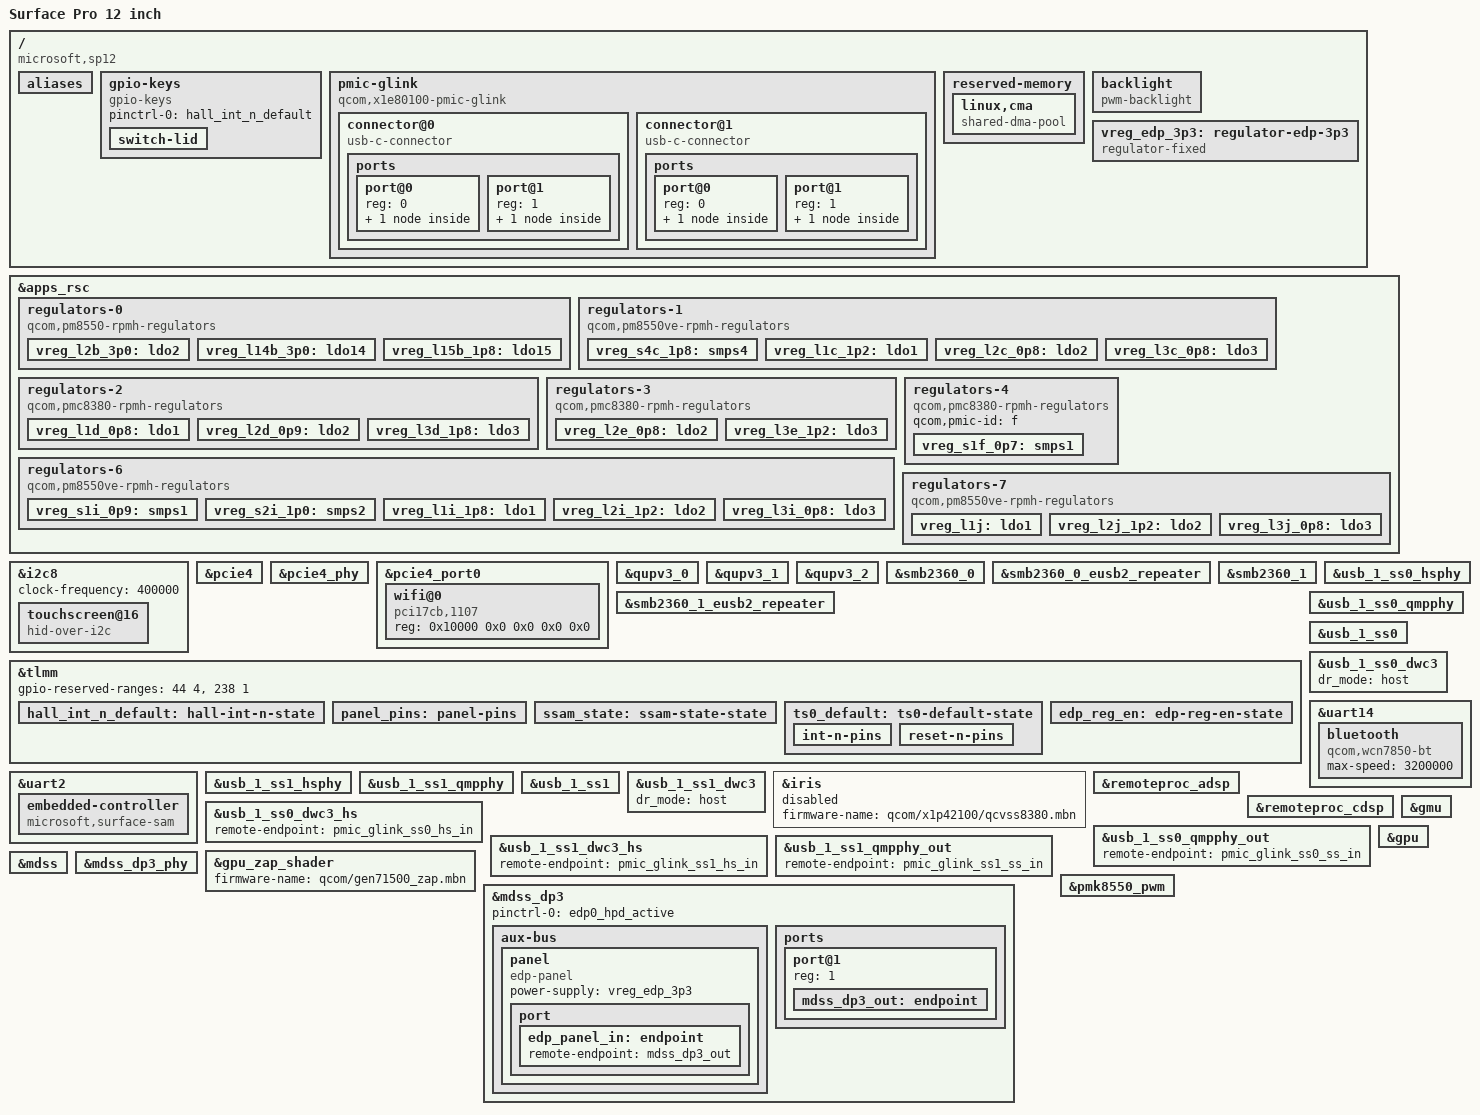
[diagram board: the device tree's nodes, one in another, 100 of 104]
// SPDX-License-Identifier: BSD-3-Clause
/*
 * Copyright (c) 2023 Qualcomm Innovation Center, Inc. All rights reserved.
 * Copyright (c) 2024, Linaro Limited
 * Copyright (c) 2025, Jens Glathe
 */

/dts-v1/;

#include <dt-bindings/gpio/gpio.h>
#include <dt-bindings/input/gpio-keys.h>
#include <dt-bindings/input/input.h>
#include <dt-bindings/pinctrl/qcom,pmic-gpio.h>
#include <dt-bindings/regulator/qcom,rpmh-regulator.h>
#include <dt-bindings/clock/qcom,x1e80100-tcsr.h>

#include "x1p42100.dtsi"
#include "x1e80100-pmics.dtsi"

/delete-node/ &pmc8380_6;
/delete-node/ &pmc8380_6_thermal;
/delete-node/ &pm8010;
/delete-node/ &pm8010_thermal;

/ {
	model = "Surface Pro 12 inch";
	compatible = "microsoft,sp12", "qcom,x1p42100";
	chassis-type = "tablet";

	aliases {
		serial0 = &uart2;
		serial1 = &uart14;
	};




	gpio-keys {
		compatible = "gpio-keys";

		pinctrl-0 = <&hall_int_n_default>;
		pinctrl-names = "default";

		switch-lid {
			gpios = <&tlmm 2 GPIO_ACTIVE_LOW>;
			linux,input-type = <EV_SW>;
			linux,code = <SW_LID>;
			wakeup-source;
			wakeup-event-action = <EV_ACT_DEASSERTED>;
		};
		
	};


	pmic-glink {
		compatible = "qcom,x1e80100-pmic-glink","qcom,sm8550-pmic-glink",
			     "qcom,pmic-glink";
		#address-cells = <1>;
		#size-cells = <0>;

		connector@0 {
			compatible = "usb-c-connector";
			reg = <0>;
			power-role = "dual";
			data-role = "host";
			
			ports {
				#address-cells = <1>;
				#size-cells = <0>;

				port@0 {
					reg = <0>;

					pmic_glink_ss0_hs_in: endpoint {
						remote-endpoint = <&usb_1_ss0_dwc3_hs>;
					};
				};

				port@1 {
					reg = <1>;

					pmic_glink_ss0_ss_in: endpoint {
						remote-endpoint = <&usb_1_ss0_qmpphy_out>;
					};
				};
			
			};
		};

		/* User-adjacent port */
		connector@1 {
			compatible = "usb-c-connector";
			reg = <1>;
			power-role = "dual";
			data-role = "host";
			
			ports {
				#address-cells = <1>;
				#size-cells = <0>;

				port@0 {
					reg = <0>;

					pmic_glink_ss1_hs_in: endpoint {
						remote-endpoint = <&usb_1_ss1_dwc3_hs>;
					};
				};

				port@1 {
					reg = <1>;

					pmic_glink_ss1_ss_in: endpoint {
						remote-endpoint = <&usb_1_ss1_qmpphy_out>;
					};
				};

			};
		};
	};

	reserved-memory {
		linux,cma {
			compatible = "shared-dma-pool";
			size = <0x0 0x8000000>;
			reusable;
			linux,cma-default;
		};
	};


	

};

&apps_rsc {
	regulators-0 {
		compatible = "qcom,pm8550-rpmh-regulators";
		qcom,pmic-id = "b";

		vdd-l1-l4-l10-supply = <&vreg_s4c_1p8>;
		vdd-l15-supply = <&vreg_s4c_1p8>;

	

		vreg_l2b_3p0: ldo2 { // usb repeater?
			regulator-name = "vreg_l2b_3p0";
			regulator-min-microvolt = <3072000>;
			regulator-max-microvolt = <3072000>;
			regulator-initial-mode = <RPMH_REGULATOR_MODE_HPM>;
			regulator-boot-on;
			
		};




		vreg_l14b_3p0: ldo14 { // usb repeater?
			regulator-name = "vreg_l14b_3p0";
			regulator-min-microvolt = <3072000>;
			regulator-max-microvolt = <3072000>;
			regulator-initial-mode = <RPMH_REGULATOR_MODE_HPM>;
		regulator-boot-on;
		};

		vreg_l15b_1p8: ldo15 { // touchscreen
			regulator-name = "vreg_l15b_1p8";
			regulator-min-microvolt = <1800000>;
			regulator-max-microvolt = <1800000>;
			regulator-initial-mode = <RPMH_REGULATOR_MODE_HPM>;
		regulator-boot-on;
			
		};

	};

	regulators-1 {
		compatible = "qcom,pm8550ve-rpmh-regulators";
		qcom,pmic-id = "c";

		vdd-l2-supply = <&vreg_s1f_0p7>;
		vdd-l3-supply = <&vreg_s1f_0p7>;

		vreg_s4c_1p8: smps4 {
			regulator-name = "vreg_s4c_1p8";
			regulator-min-microvolt = <1856000>;
			regulator-max-microvolt = <2000000>;
			regulator-initial-mode = <RPMH_REGULATOR_MODE_HPM>;
		regulator-boot-on;
		};

		vreg_l1c_1p2: ldo1 {
			regulator-name = "vreg_l1c_1p2";
			regulator-min-microvolt = <1200000>;
			regulator-max-microvolt = <1200000>;
			regulator-initial-mode = <RPMH_REGULATOR_MODE_HPM>;
		regulator-boot-on;
		};

		vreg_l2c_0p8: ldo2 {
			regulator-name = "vreg_l2c_0p8";
			regulator-min-microvolt = <880000>;
			regulator-max-microvolt = <880000>;
			regulator-initial-mode = <RPMH_REGULATOR_MODE_HPM>;
			regulator-boot-on;
		};

		vreg_l3c_0p8: ldo3 {
			regulator-name = "vreg_l3c_0p8";
			regulator-min-microvolt = <912000>;
			regulator-max-microvolt = <912000>;
			regulator-initial-mode = <RPMH_REGULATOR_MODE_HPM>;
		regulator-boot-on;
		};
	};

	regulators-2 {
		compatible = "qcom,pmc8380-rpmh-regulators";
		qcom,pmic-id = "d";

		vdd-l1-supply = <&vreg_s1f_0p7>;
		vdd-l2-supply = <&vreg_s1f_0p7>;
		vdd-l3-supply = <&vreg_s4c_1p8>;

		vreg_l1d_0p8: ldo1 {
			regulator-name = "vreg_l1d_0p8";
			regulator-min-microvolt = <880000>;
			regulator-max-microvolt = <880000>;
			regulator-initial-mode = <RPMH_REGULATOR_MODE_HPM>;
			regulator-boot-on;
			
		};

		vreg_l2d_0p9: ldo2 { // other usb
			regulator-name = "vreg_l2d_0p9";
			regulator-min-microvolt = <912000>;
			regulator-max-microvolt = <912000>;
			regulator-initial-mode = <RPMH_REGULATOR_MODE_HPM>;
		regulator-boot-on;
		};

		vreg_l3d_1p8: ldo3 { // usb repeater
			regulator-name = "vreg_l3d_1p8";
			regulator-min-microvolt = <1800000>;
			regulator-max-microvolt = <1800000>;
			regulator-initial-mode = <RPMH_REGULATOR_MODE_HPM>;
			regulator-boot-on;
			
		};
	};

	regulators-3 {
		compatible = "qcom,pmc8380-rpmh-regulators";
		qcom,pmic-id = "e";

		vdd-l2-supply = <&vreg_s1f_0p7>;

		vreg_l2e_0p8: ldo2 {
			regulator-name = "vreg_l2e_0p8";
			regulator-min-microvolt = <880000>;
			regulator-max-microvolt = <880000>;
			regulator-initial-mode = <RPMH_REGULATOR_MODE_HPM>;
			regulator-boot-on;
			regulator-always-on;
		};

		vreg_l3e_1p2: ldo3 { // pci4, usb
			regulator-name = "vreg_l3e_1p2";
			regulator-min-microvolt = <1200000>;
			regulator-max-microvolt = <1200000>;
			regulator-initial-mode = <RPMH_REGULATOR_MODE_HPM>;
			regulator-boot-on;
			regulator-always-on;
		};
	};

	regulators-4 {
		compatible = "qcom,pmc8380-rpmh-regulators";
		qcom,pmic-id = "f";


		vreg_s1f_0p7: smps1 {
			regulator-name = "vreg_s1f_0p7";
			regulator-min-microvolt = <700000>;
			regulator-max-microvolt = <1100000>;
			regulator-initial-mode = <RPMH_REGULATOR_MODE_HPM>;
		regulator-boot-on;
		};
	};

	regulators-6 {
		compatible = "qcom,pm8550ve-rpmh-regulators";
		qcom,pmic-id = "i";

		vdd-l1-supply = <&vreg_s4c_1p8>;
		vdd-l3-supply = <&vreg_s1f_0p7>;

		vreg_s1i_0p9: smps1 {
			regulator-name = "vreg_s1i_0p9";
			regulator-min-microvolt = <900000>;
			regulator-max-microvolt = <920000>;
			regulator-initial-mode = <RPMH_REGULATOR_MODE_HPM>;
		regulator-boot-on;
		};

		vreg_s2i_1p0: smps2 {
			regulator-name = "vreg_s2i_1p0";
			regulator-min-microvolt = <1000000>;
			regulator-max-microvolt = <1100000>;
			regulator-initial-mode = <RPMH_REGULATOR_MODE_HPM>;
			regulator-boot-on;
		};

		vreg_l1i_1p8: ldo1 {
			regulator-name = "vreg_l1i_1p8";
			regulator-min-microvolt = <1800000>;
			regulator-max-microvolt = <1800000>;
			regulator-initial-mode = <RPMH_REGULATOR_MODE_HPM>;
			regulator-boot-on;
			
		};

		vreg_l2i_1p2: ldo2 {
			regulator-name = "vreg_l2i_1p2";
			regulator-min-microvolt = <1200000>;
			regulator-max-microvolt = <1200000>;
			regulator-initial-mode = <RPMH_REGULATOR_MODE_HPM>;
			regulator-boot-on;
			regulator-always-on;
		};

		vreg_l3i_0p8: ldo3 { // pcie4
			regulator-name = "vreg_l3i_0p8";
			regulator-min-microvolt = <880000>;
			regulator-max-microvolt = <880000>;
			regulator-initial-mode = <RPMH_REGULATOR_MODE_HPM>;
			regulator-boot-on;
			regulator-always-on;
		};
	};

	regulators-7 {
		compatible = "qcom,pm8550ve-rpmh-regulators";
		qcom,pmic-id = "j";

		vdd-l1-supply = <&vreg_s1f_0p7>;
		vdd-l3-supply = <&vreg_s1f_0p7>;

		

		vreg_l1j: ldo1 {
			regulator-name = "vreg_l1j";
			regulator-min-microvolt = <912000>;
			regulator-max-microvolt = <912000>;
			regulator-initial-mode = <RPMH_REGULATOR_MODE_HPM>;
			regulator-boot-on;
			regulator-always-on;
			
		};

		vreg_l2j_1p2: ldo2 { // usb power
			regulator-name = "vreg_l2j_1p2";
			regulator-min-microvolt = <1256000>;
			regulator-max-microvolt = <1256000>;
			regulator-initial-mode = <RPMH_REGULATOR_MODE_HPM>;
			regulator-boot-on;
			regulator-always-on;
			
		};

		vreg_l3j_0p8: ldo3 { // usb and display power, also pci3?
			regulator-name = "vreg_l3j_0p8";
			regulator-min-microvolt = <880000>;
			regulator-max-microvolt = <880000>;
			regulator-initial-mode = <RPMH_REGULATOR_MODE_HPM>;
			regulator-boot-on;
			regulator-always-on;
			
		};


	};
};
















&i2c8 {
	clock-frequency = <400000>;

	status = "okay";

	/* ILIT2911 or GTCH1563 */
	touchscreen@16 {
		compatible = "hid-over-i2c";
		reg = <0x16>;

		hid-descr-addr = <0x1>;
		interrupts-extended = <&tlmm 51 IRQ_TYPE_LEVEL_LOW>;


		vddl-supply = <&vreg_l15b_1p8>;

		pinctrl-0 = <&ts0_default>;
		pinctrl-names = "default";
	};
};


&pcie4 {
	status = "okay";

	vdda-phy-supply = <&vreg_l3e_1p2>;
	vdd-phy-supply = <&vreg_l3j_0p8>;
	vdda-pll-supply = <&vreg_l3i_0p8>;
};

&pcie4_phy {

	status = "okay";
};

&pcie4_port0 {
	wifi@0 {
		compatible = "pci17cb,1107";
		reg = <0x10000 0x0 0x0 0x0 0x0>;
	};
};



&qupv3_0 {
	status = "okay";
};

&qupv3_1 {
	status = "okay";
};

&qupv3_2 {
	status = "okay";
};

&smb2360_0 {
	status = "okay";
};

&smb2360_0_eusb2_repeater {
	vdd18-supply = <&vreg_l3d_1p8>;
	vdd3-supply = <&vreg_l2b_3p0>;
};

&smb2360_1 {
	status = "okay";
};

&smb2360_1_eusb2_repeater {
	vdd18-supply = <&vreg_l3d_1p8>;
	vdd3-supply = <&vreg_l14b_3p0>;
};




&tlmm {
	gpio-reserved-ranges = <44 4>,
		<238 1>; /* UFS Reset */



	hall_int_n_default: hall-int-n-state {
		pins = "gpio2";
		function = "gpio";
		bias-disable;
	};



	panel_pins: panel-pins {
		pins = "gpio29";
		function = "gpio";
		drive-strength = <2>;
		bias-disable;
		output-low;
	};




	ssam_state: ssam-state-state {
		pins = "gpio91";
		function = "gpio";
		bias-disable;
	};

	ts0_default: ts0-default-state {
		int-n-pins {
			pins = "gpio51";
			function = "gpio";
			bias-disable;
		};

		reset-n-pins {
			pins = "gpio52";
			function = "gpio";
			output-high;
			drive-strength = <16>;
		};
	};


};

&uart2 {
	status = "okay";

	embedded-controller {
		compatible = "microsoft,surface-sam";

		interrupts-extended = <&tlmm 91 IRQ_TYPE_EDGE_RISING>;

		current-speed = <4000000>;

		pinctrl-0 = <&ssam_state>;
		pinctrl-names = "default";
	};
};

&usb_1_ss0_hsphy {
	vdd-supply = <&vreg_l3j_0p8>;
	vdda12-supply = <&vreg_l2j_1p2>;

	phys = <&smb2360_0_eusb2_repeater>;

	status = "okay";
};

&usb_1_ss0_qmpphy {
	vdda-phy-supply = <&vreg_l3e_1p2>;
	vdda-pll-supply = <&vreg_l1j>;

	status = "okay";
};

&usb_1_ss0 {
	status = "okay";
};

&usb_1_ss0_dwc3 {
	dr_mode = "host";
};


&uart14 {
	status = "okay";

	bluetooth {
		compatible = "qcom,wcn7850-bt";
		max-speed = <3200000>;
	};
};



&usb_1_ss1_hsphy {
	vdd-supply = <&vreg_l3j_0p8>;
	vdda12-supply = <&vreg_l2j_1p2>;

	phys = <&smb2360_1_eusb2_repeater>;

	status = "okay";
};

&usb_1_ss1_qmpphy {
	vdda-phy-supply = <&vreg_l2j_1p2>;
	vdda-pll-supply = <&vreg_l2d_0p9>;

	status = "okay";
};

&usb_1_ss1 {
	status = "okay";
};

&usb_1_ss1_dwc3 {
	dr_mode = "host";
};


&iris {
	firmware-name = "qcom/x1p42100/qcvss8380.mbn";

	status = "disabled";
};



&remoteproc_adsp {
	firmware-name = "qcom/x1p42100/qcadsp8380.mbn", "qcom/x1p42100/adsp_dtbs.elf";

	status = "okay";
};

&remoteproc_cdsp {
	firmware-name = "qcom/x1p42100/qccdsp8380.mbn", "qcom/x1p42100/cdsp_dtbs.elf";

	status = "okay";
};

&usb_1_ss0_dwc3_hs {
	remote-endpoint = <&pmic_glink_ss0_hs_in>;
};

&usb_1_ss0_qmpphy_out {
	remote-endpoint = <&pmic_glink_ss0_ss_in>;
};

&usb_1_ss1_dwc3_hs {
	remote-endpoint = <&pmic_glink_ss1_hs_in>;
};

&usb_1_ss1_qmpphy_out {
	remote-endpoint = <&pmic_glink_ss1_ss_in>;
};



/* DISPLAY */

// Gpu power management
&gmu {
	//status = "okay";
};

// Graphics Pocessing Unit
&gpu {
	status = "okay";
};

&gpu_zap_shader {
		firmware-name = "qcom/gen71500_zap.mbn";
};

// Display system
&mdss {
	status = "okay";
};

// Internal Display Port
&mdss_dp3_phy {
	vdda-phy-supply = <&vreg_l3j_0p8>;
	vdda-pll-supply = <&vreg_l2j_1p2>;

	status = "okay";
};

&mdss_dp3 {
	/delete-property/ #sound-dai-cells;

	pinctrl-names = "default";
	pinctrl-0 = <&edp0_hpd_active>;

	status = "okay";

	aux-bus {
		panel {
			compatible = "edp-panel";

			power-supply = <&vreg_edp_3p3>;

			port {
				edp_panel_in: endpoint {
					remote-endpoint = <&mdss_dp3_out>;
				};
			};
		};
	};

	ports {
		port@1 {
			reg = <1>;

			mdss_dp3_out: endpoint {
				data-lanes = <0 1 2 3>;
				link-frequencies = /bits/ 64 <1620000000 2700000000 5400000000 8100000000>;

				remote-endpoint = <&edp_panel_in>;
			};
		};
	};
};

// Backlight
/ {
	backlight: backlight {
		compatible = "pwm-backlight";
		pwms = <&pmk8550_pwm 0 5000000>;		

		power-supply = <&vreg_edp_3p3>;

	};


	// Backlight power regulator
	vreg_edp_3p3: regulator-edp-3p3 {
		compatible = "regulator-fixed";

		regulator-name = "VREG_EDP_3P3";
		regulator-min-microvolt = <3300000>;
		regulator-max-microvolt = <3300000>;

		gpio = <&tlmm 70 GPIO_ACTIVE_HIGH>;
		enable-active-high;

		pinctrl-0 = <&edp_reg_en>;
		pinctrl-names = "default";

		regulator-boot-on;
		
	};	

};

// Backlight PWM Controller
&pmk8550_pwm {
	status = "okay";
};

// backlight power control pins
&tlmm {
		edp_reg_en: edp-reg-en-state {
		pins = "gpio70";
		function = "gpio";
		drive-strength = <2>;
		bias-disable;
		output-high;
	};
};

